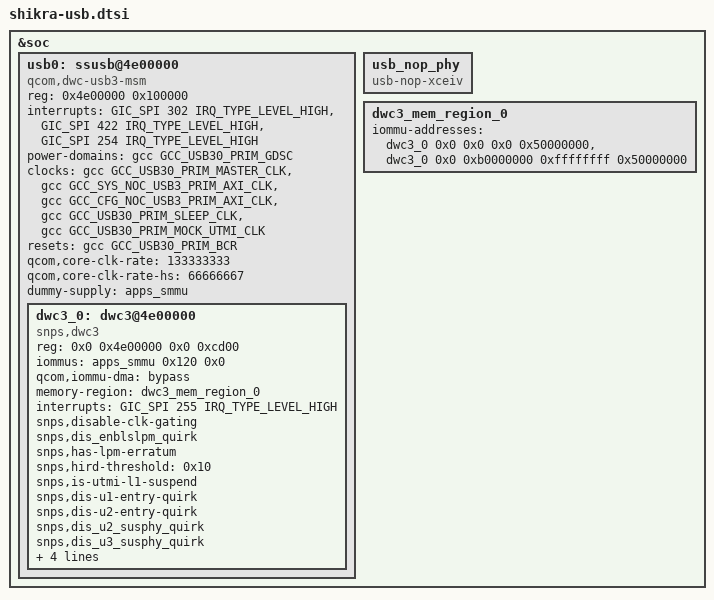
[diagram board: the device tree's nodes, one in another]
// SPDX-License-Identifier: BSD-3-Clause
/*
 * Copyright (c) Qualcomm Technologies, Inc. and/or its subsidiaries.
 */

#include <dt-bindings/clock/qcom,shikra-gcc.h>

&soc {
	/* Primary USB port related controller */
	usb0: ssusb@4e00000 {
		compatible = "qcom,dwc-usb3-msm";
		reg = <0x4e00000 0x100000>;
		reg-names = "core_base";

		#address-cells = <2>;
		#size-cells = <2>;
		ranges;

		interrupts = <GIC_SPI 302 IRQ_TYPE_LEVEL_HIGH>,
			<GIC_SPI 422 IRQ_TYPE_LEVEL_HIGH>,
			<GIC_SPI 254 IRQ_TYPE_LEVEL_HIGH>;
		interrupt-names = "pwr_event_irq", "ss_phy_irq", "hs_phy_irq";

		power-domains = <&gcc GCC_USB30_PRIM_GDSC>;
		clocks = <&gcc  GCC_USB30_PRIM_MASTER_CLK>,
			<&gcc GCC_SYS_NOC_USB3_PRIM_AXI_CLK>,
			<&gcc GCC_CFG_NOC_USB3_PRIM_AXI_CLK>,
			<&gcc GCC_USB30_PRIM_SLEEP_CLK>,
			<&gcc GCC_USB30_PRIM_MOCK_UTMI_CLK>;
		clock-names = "core_clk", "iface_clk", "bus_aggr_clk",
				"sleep_clk", "utmi_clk";

		resets = <&gcc GCC_USB30_PRIM_BCR>;
		reset-names = "core_reset";

		qcom,core-clk-rate = <133333333>;
		qcom,core-clk-rate-hs = <66666667>;

		dummy-supply = <&apps_smmu>;

		dwc3_0: dwc3@4e00000 {
			compatible = "snps,dwc3";
			reg = <0x0 0x4e00000 0x0 0xcd00>;
			iommus = <&apps_smmu 0x120 0x0>;
			qcom,iommu-dma = "bypass";
			memory-region = <&dwc3_mem_region_0>;
			interrupts = <GIC_SPI 255 IRQ_TYPE_LEVEL_HIGH>;
			snps,disable-clk-gating;
			snps,dis_enblslpm_quirk;
			snps,has-lpm-erratum;
			snps,hird-threshold = /bits/ 8 <0x10>;
			snps,is-utmi-l1-suspend;
			snps,dis-u1-entry-quirk;
			snps,dis-u2-entry-quirk;
			snps,dis_u2_susphy_quirk;
			snps,dis_u3_susphy_quirk;
			snps,ssp-u3-u0-quirk;
			maximum-speed = "super-speed";
			dr_mode = "otg";
			usb-role-switch;
		};
	};

	usb_nop_phy: usb_nop_phy {
		     compatible = "usb-nop-xceiv";
	};

	dwc3_mem_region_0: dwc3_mem_region_0 {
		iommu-addresses = <&dwc3_0 0x0 0x0 0x0 0x50000000>,
					<&dwc3_0 0x0 0xb0000000 0xffffffff 0x50000000>;
	};
};
